AUTOSAR XML (schema 4-0-3)
package /ARPackage_IntTst_Mem
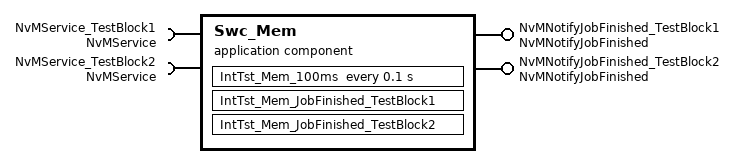
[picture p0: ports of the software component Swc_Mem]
  application sw component type Swc_Mem
    provide port NvMNotifyJobFinished_TestBlock1: server-com-spec{operation=JobFinished, queue-length=1}, provided-interface=NvMNotifyJobFinished
    provide port NvMNotifyJobFinished_TestBlock2: server-com-spec{operation=JobFinished, queue-length=1}, provided-interface=NvMNotifyJobFinished
    require port NvMService_TestBlock1: required-com-specs=[GetErrorStatus, ReadBlock, WriteBlock], required-interface=NvMService
    require port NvMService_TestBlock2: required-com-specs=[GetErrorStatus, ReadBlock, WriteBlock], required-interface=NvMService
    behavior SwcIB_IntTst_Mem
      operation invoked event OIE_IntTst_Mem_JobFinished_TestBlock1: start-on-event=IntTst_Mem_JobFinished_TestBlock1, operation=NvMNotifyJobFinished_TestBlock1.JobFinished
      operation invoked event OIE_IntTst_Mem_JobFinished_TestBlock2: start-on-event=IntTst_Mem_JobFinished_TestBlock2, operation=NvMNotifyJobFinished_TestBlock2.JobFinished
      timing event TE_IntTst_Mem_100ms: start-on-event=IntTst_Mem_100ms, period=0.1
      runnable IntTst_Mem_JobFinished_TestBlock1
      runnable IntTst_Mem_JobFinished_TestBlock2
      runnable IntTst_Mem_100ms
        6 x sync call:
          SynchronousServerCallPoint_GetErrorStatus_TestBlock1: operation=NvMService_TestBlock1.GetErrorStatus
          SynchronousServerCallPoint_ReadBlock_TestBlock1: operation=NvMService_TestBlock1.ReadBlock
          SynchronousServerCallPoint_WriteBlock_TestBlock1: operation=NvMService_TestBlock1.WriteBlock
          SynchronousServerCallPoint_GetErrorStatus_TestBlock2: operation=NvMService_TestBlock2.GetErrorStatus
          SynchronousServerCallPoint_ReadBlock_TestBlock2: operation=NvMService_TestBlock2.ReadBlock
          SynchronousServerCallPoint_WriteBlock_TestBlock2: operation=NvMService_TestBlock2.WriteBlock
